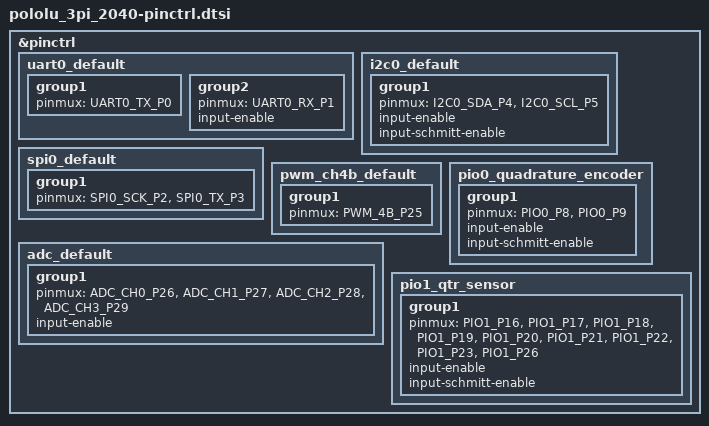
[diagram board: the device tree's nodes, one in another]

#include <zephyr/dt-bindings/pinctrl/rpi-pico-rp2040-pinctrl.h>

&pinctrl
{
    uart0_default: uart0_default {
		group1 {
			pinmux = <UART0_TX_P0>;
		};
		group2 {
			pinmux = <UART0_RX_P1>;
			input-enable;
		};
	};

    i2c0_default: i2c0_default{
        group1{
            pinmux = <I2C0_SDA_P4>, <I2C0_SCL_P5>;
            input-enable;
            input-schmitt-enable;
        };
    };

    spi0_default: spi0_default {
		group1 {
			pinmux = <SPI0_SCK_P2>, <SPI0_TX_P3>;
		};
	};

    pwm_ch4b_default: pwm_ch4b_default {
		group1 {
			pinmux = <PWM_4B_P25>;
		};
	};

	adc_default: adc_default {
		group1 {
			pinmux = <ADC_CH0_P26>, <ADC_CH1_P27>, <ADC_CH2_P28>, <ADC_CH3_P29>;
			input-enable;
		};
	};

    pio0_quadrature_encoder: pio0_quadrature_encoder{
        group1{
            pinmux = <PIO0_P8>, <PIO0_P9>;
            input-enable;
            input-schmitt-enable;
        };
    };

    pio1_qtr_sensor: pio1_qtr_sensor{
        group1{
            pinmux = <PIO1_P16>, <PIO1_P17>, <PIO1_P18>, <PIO1_P19>, <PIO1_P20>, <PIO1_P21>, <PIO1_P22>, <PIO1_P23>, <PIO1_P26>;
            input-enable;
            input-schmitt-enable;
        };
    };
};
